# MPU_367.0 register map
Vendor: Texas Instruments
Peripheral module from a debugger description file (folder msp430).
Registers are 16-bit, read-write, no defined reset value unless marked. A register's access mark holds for its fields unless they carry their own. Offsets are as the file gives them; lines under a group give offsets from that group; [hi:lo] are bit positions; {n}, {i} and the like mark numbered series; 'fields as' and 'values as' point back to an identical list; <NAME> marks a mode.

## MPU
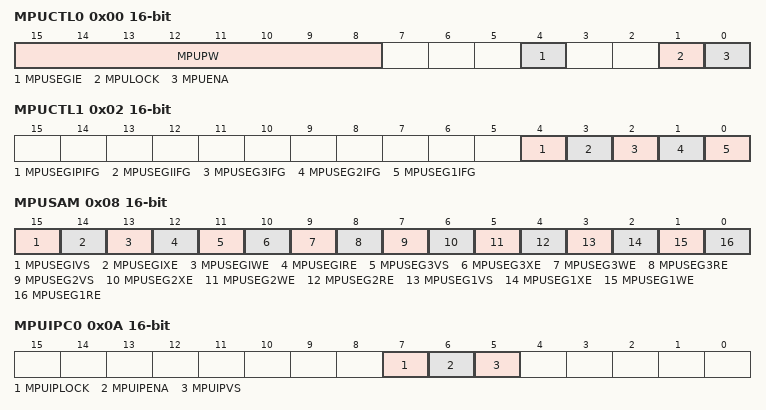
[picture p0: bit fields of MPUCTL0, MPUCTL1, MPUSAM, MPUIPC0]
0x00 MPUCTL0 — Memory Protection Unit Control 0
  [15:8] MPUPW — MPU Password
  [4] MPUSEGIE — Enable NMI Event if a Segment violation
    0=DISABLE (Segment violation interrupt disabled); 1=ENABLE (Segment violation interrupt enabled)
  [1] MPULOCK
    0=OPEN; 1=LOCK (Locked)
  [0] MPUENA — MPU Enable
    0=DISABLE (Disabled); 1=ENABLE (Enabled)
0x02 MPUCTL1 — Memory Protection Unit Control 1
  [4] MPUSEGIPIFG — IP Encapsulation Access Violation Interrupt Flag
    0=MPUSEG1IFG_0 (No interrupt pending); 1=MPUSEG1IFG_1 (Interrupt pending)
  [3] MPUSEGIIFG — User Information Memory Violation Interrupt Flag
    0=No interrupt pending; 1=Interrupt pending
  [2] MPUSEG3IFG — Main Memory Segment 3 Violation Interrupt Flag
    values as MPUSEGIPIFG
  [1] MPUSEG2IFG — Main Memory Segment 2 Violation Interrupt Flag
    0=No interrupt pending; 1=Interrupt pending
  [0] MPUSEG1IFG — Main Memory Segment 1 Violation Interrupt Flag
    0=No interrupt pending; 1=Interrupt pending
0x04 MPUSEGB2 access not given — Memory Protection Unit Segmentation Border 2 Register
0x06 MPUSEGB1 access not given — Memory Protection Unit Segmentation Border 1 Register
0x08 MPUSAM — Memory Protection Unit Segmentation Access Management Register
  [15] MPUSEGIVS — MPU User Information Memory Segment Violation Select
    0=Violation in User Information Memory asserts the MPUSEGIIFG bit and executes a SNMI if enabled by MPUSEGIE =1; 1=Violation in User Information Memory asserts the MPUSEGIIFG bit and executes a PUC
  [14] MPUSEGIXE — MPU User Information Memory Segment Execute Enable
    0=DISABLE (Execute code on User Information Memory causes a violation); 1=ENABLE (Execute code on User Information Memory is allowed)
  [13] MPUSEGIWE — MPU User Information Memory Segment Write Enable.
    0=DISABLE (Write on User Information Memory causes a violation); 1=ENABLE (Write on User Information Memory is allowed)
  [12] MPUSEGIRE — MPU User Information Memory Segment Read Enable
    0=DISABLE (Read on User Information Memory causes a violation if MPUSEGIWE=MPUSEGIXE=0); 1=ENABLE (Read on User Information Memory is allowed)
  [11] MPUSEG3VS — MPU Main Memory Segment 3 Violation Select
    0=Violation in Main Memory Segment 3 asserts the MPUSEG3IFG bit and executes a SNMI if enabled by MPUSEGIE = 1; 1=Violation in Main Memory Segment 3 asserts the MPUSEG3IFG bit and executes a PUC
  [10] MPUSEG3XE — MPU Main Memory Segment 3 Execute Enable
    0=DISABLE (Execute code on Main Memory Segment 3 causes a violation); 1=ENABLE (Execute code on Main Memory Segment 3 is allowed)
  [9] MPUSEG3WE — MPU Main Memory Segment 3 Write Enable
    0=DISABLE (Write on Main Memory Segment 3 causes a violation); 1=ENABLE (Write on Main Memory Segment 3 is allowed)
  [8] MPUSEG3RE — MPU Main Memory Segment 3 Read Enable
    0=DISABLE (Read on Main Memory Segment 3 causes a violation if MPUSEG3WE = MPUSEG3XE = 0); 1=ENABLE (Read on Main Memory Segment 3 is allowed)
  [7] MPUSEG2VS — MPU Main Memory Segment 2 Violation Select
    0=Violation in Main Memory Segment 2 asserts the MPUSEG2IFG bit and executes a SNMI if enabled by MPUSEGIE = 1; 1=Violation in Main Memory Segment 2 asserts the MPUSEG2IFG bit and executes a PUC
  [6] MPUSEG2XE — MPU Main Memory Segment 2 Execute Enable
    0=DISABLE (Execute code on Main Memory Segment 2 causes a violation); 1=ENABLE (Execute code on Main Memory Segment 2 is allowed)
  [5] MPUSEG2WE — MPU Main Memory Segment 2 Write Enable
    0=DISABLE (Write on Main Memory Segment 2 causes a violation); 1=ENABLE (Write on Main Memory Segment 2 is allowed)
  [4] MPUSEG2RE — MPU Main Memory Segment 2 Read Enable
    0=DISABLE (Read on Main Memory Segment 2 causes a violation if MPUSEG2WE = MPUSEG2XE = 0); 1=ENABLE (Read on Main Memory Segment 2 is allowed)
  [3] MPUSEG1VS — MPU Main Memory Segment 1 Violation Select
    0=Violation in Main Memory Segment 1 asserts the MPUSEG1IFG bit and executes a SNMI if enabled by MPUSEGIE = 1; 1=Violation in Main Memory Segment 1 asserts the MPUSEG1IFG bit and executes a PUC
  [2] MPUSEG1XE — MPU Main Memory Segment 1 Execute Enable
    0=DISABLE (Execute code on Main Memory Segment 1 causes a violation); 1=ENABLE (Execute code on Main Memory Segment 1 is allowed)
  [1] MPUSEG1WE — MPU Main Memory Segment 1 Write Enable
    0=DISABLE (Write on Main Memory Segment 1 causes a violation); 1=ENABLE (Write on Main Memory Segment 1 is allowed)
  [0] MPUSEG1RE — MPU Main Memory Segment 1 Read Enable
    0=DISABLE (Read on Main Memory Segment 1 causes a violation if MPUSEG1WE = MPUSEG1XE = 0); 1=ENABLE (Read on Main Memory Segment 1 is allowed)
0x0A MPUIPC0 — Memory Protection Unit IP Control 0 Register
  [7] MPUIPLOCK — MPU IP Encapsulation Lock
    0=OPEN; 1=LOCK (Locked)
  [6] MPUIPENA — MPU IP Encapsulation Enable
    0=DISABLE (Disabled); 1=ENABLE (Enabled)
  [5] MPUIPVS — MPU IP Encapsulation segment Violation Select
    0=Violation in Main Memory Segment 1 asserts the MPUSEGPIFG bit and executes a SNMI if enabled by MPUSEGIE = 1; 1=Violation in Main Memory Segment 1 asserts the MPUSEGPIFG bit and executes a PUC
0x0C MPUIPSEGB2 access not given — Memory Protection Unit IP Encapsulation Segment Border 2 Register
0x0E MPUIPSEGB1 access not given — Memory Protection Unit IP Encapsulation Segment Border 1 Register
